# GD32E53x register map
File version: 1.0
CPU: CM33 r0p4, little endian, MPU, FPU, 4 interrupt priority bits
Registers are 32-bit, read-write, reset 0x0 unless marked. A register's access mark holds for its fields unless they carry their own. Offsets are from the block's base; [hi:lo] are bit positions.

## TIMER14 — General level3 timer
Base 0x40014000
Same registers: TIMER42 0x4000E000, TIMER43 0x4000E400, TIMER44 0x4000E800, TIMER41 0x40014400, TIMER40 0x40014C00
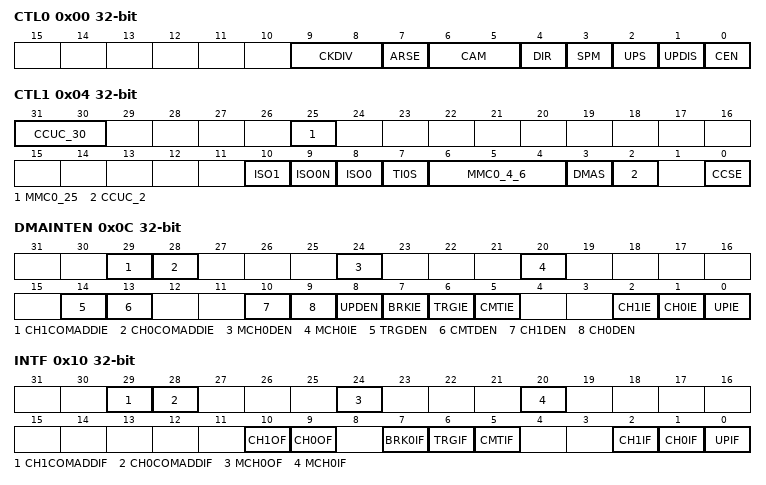
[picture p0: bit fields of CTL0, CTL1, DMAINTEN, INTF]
0x00 CTL0 — Control register 0
  [9:8] CKDIV — Clock division
  [7] ARSE — Auto-reload shadow enable
  [6:5] CAM — Counter align mode selection
  [4] DIR — Direction
  [3] SPM — Single pulse mode
  [2] UPS — Update source
  [1] UPDIS — Update disable
  [0] CEN — Counter enable
0x04 CTL1 — Control register 1
  [31:30] CCUC_30 — Commutation control shadow register update control
  [25] MMC0_25 — Master mode control 0
  [10] ISO1 — Idle state of channel 1 output
  [9] ISO0N — Idle state of multi mode channel 0 complementary output
  [8] ISO0 — Idle state of channel 0 output
  [7] TI0S — Channel 0 trigger input selection
  [6:4] MMC0_4_6 — Master mode control 0
  [3] DMAS — DMA request source selection
  [2] CCUC_2 — Commutation control shadow register update control
  [0] CCSE — Commutation control shadow enable
0x08 SMCFG — Slave mode configuration register
  [7] MSM — Master-slave mode
0x0C DMAINTEN — DMA and interrupt enable register
  [29] CH1COMADDIE — Channel 1 additional compare interrupt enable
  [28] CH0COMADDIE — Channel 0 additional compare interrupt enable
  [24] MCH0DEN — Multi mode channel 0 capture/compare DMA request enable
  [20] MCH0IE — Multi mode channel 0 capture/compare interrupt enable
  [14] TRGDEN — Trigger DMA request enable
  [13] CMTDEN — Commutation DMA request enable
  [10] CH1DEN — Channel 1 capture/compare DMA request enable
  [9] CH0DEN — Channel 0 capture/compare DMA request enable
  [8] UPDEN — Update DMA request enable
  [7] BRKIE — Break interrupt enable
  [6] TRGIE — Trigger interrupt enable
  [5] CMTIE — Commutation interrupt enable
  [2] CH1IE — Channel 1 capture/compare interrupt enable
  [1] CH0IE — Channel 0 capture/compare interrupt enable
  [0] UPIE — Update interrupt enable
0x10 INTF — Interrupt flag register
  [29] CH1COMADDIF — Channel 1 additional compare interrupt flag.
  [28] CH0COMADDIF — Channel 0 additional compare interrupt flag.
  [24] MCH0OF — Multi mode channel 0 over capture flag
  [20] MCH0IF — Multi mode channel 0 capture/compare interrupt flag
  [10] CH1OF — Channel 1 over capture flag
  [9] CH0OF — Channel 0 over capture flag
  [7] BRK0IF — BREAK0 interrupt flag
  [6] TRGIF — Trigger interrupt flag
  [5] CMTIF — Channel commutation interrupt flag
  [2] CH1IF — Channel 1 capture/compare interrupt flag
  [1] CH0IF — Channel 0 capture/compare interrupt flag
  [0] UPIF — Update interrupt flag
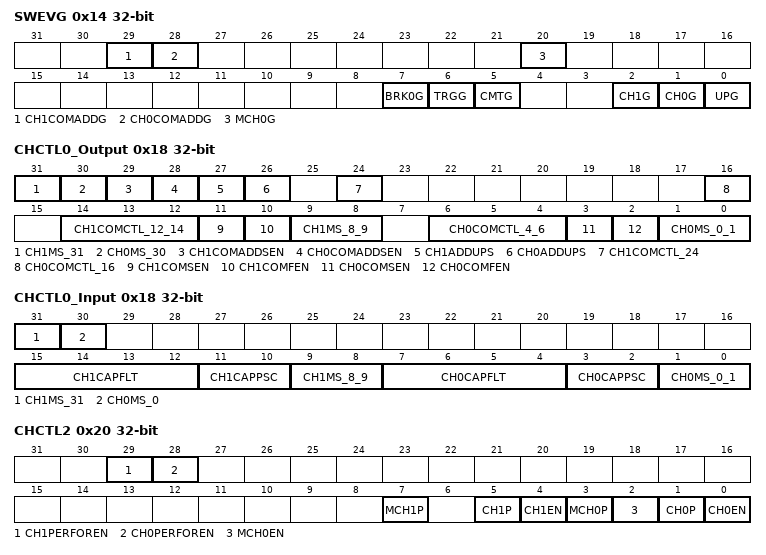
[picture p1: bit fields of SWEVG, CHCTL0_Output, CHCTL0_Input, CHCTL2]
0x14 SWEVG wo — Software event generation register
  [29] CH1COMADDG — Channel 1 additional compare event generation.
  [28] CH0COMADDG — Channel 0 additional compare event generation.
  [20] MCH0G — Multi mode channel 0 capture or compare event generation.
  [7] BRK0G — BREAK0 event generation
  [6] TRGG — Trigger event generation
  [5] CMTG — Channel commutation event generation
  [2] CH1G — Channel 1 capture or compare event generation
  [1] CH0G — Channel 0 capture or compare event generation
  [0] UPG — Update event generation
0x18 CHCTL0_Output — Channel control register 0 (output mode)
  [31] CH1MS_31 — Channel 1 I/O mode selection
  [30] CH0MS_30 — Channel 0 I/O mode selection
  [29] CH1COMADDSEN — Channel 1 additional compare output shadow enable
  [28] CH0COMADDSEN — Channel 0 additional compare output shadow enable
  [27] CH1ADDUPS — Channel 1 additional update source
  [26] CH0ADDUPS — Channel 0 additional update source
  [24] CH1COMCTL_24 — Channel 1 compare output control
  [16] CH0COMCTL_16 — Channel 0 compare output control
  [14:12] CH1COMCTL_12_14 — Channel 1 compare output control
  [11] CH1COMSEN — Channel 1 output compare shadow enable
  [10] CH1COMFEN — Channel 1 output compare fast enable
  [9:8] CH1MS_8_9 — Channel 1 mode selection
  [6:4] CH0COMCTL_4_6 — Channel 0 compare output control
  [3] CH0COMSEN — Channel 0 compare output shadow enable
  [2] CH0COMFEN — Channel 0 output compare fast enable
  [1:0] CH0MS_0_1 — Channel 0 I/O mode selection
0x18 CHCTL0_Input (alternate view of CHCTL0_Output) — Channel control register 0 (input mode)
  [31] CH1MS_31 — Channel 1 I/O mode selection
  [30] CH0MS_0 — Channel 0 I/O mode selection
  [15:12] CH1CAPFLT — Channel 1 input capture filter control
  [11:10] CH1CAPPSC — Channel 1 input capture prescaler
  [9:8] CH1MS_8_9 — Channel 1 mode selection
  [7:4] CH0CAPFLT — Channel 0 input capture filter control
  [3:2] CH0CAPPSC — Channel 0 input capture prescaler
  [1:0] CH0MS_0_1 — Channel 0 mode selection
0x20 CHCTL2 — Channel control register 2
  [29] CH1PERFOREN — Channel 1 in the composite PWM mode, the period point match moment O1CPRE level setting
  [28] CH0PERFOREN — Channel 0 in the composite PWM mode, the period point match moment O0CPRE level setting
  [7] MCH1P — Multi mode channel 1 output polarity
  [5] CH1P — Channel 1 capture/compare polarity
  [4] CH1EN — Channel 1 capture/compare enable
  [3] MCH0P — Multi mode channel 0 output polarity
  [2] MCH0EN — Multi mode channel 0 capture/compare enable
  [1] CH0P — Channel 0 capture/compare polarity
  [0] CH0EN — Channel 0 capture/compare enable
0x24 CNT — Counter register
  [15:0] CNT — This bit-field indicates the current counter value. Writing to this bit-field can change the value of the counter.
0x28 PSC — Prescaler register
  [15:0] PSC — Prescaler value of the counter clock
0x2C CAR reset 0xFFFF — Counter auto reload register
  [15:0] CARL — Counter auto reload value
0x30 CREP0 — Counter repetition register 0
  [7:0] CREP0 — Counter repetition value 0
0x34 CH0CV — Channel 0 capture/compare value register
  [15:0] CH0VAL — Capture/compare value of channel 0
0x38 CH1CV — Channel 1 capture/compare value register
  [15:0] CH1VAL — Capture/compare value of channel 1
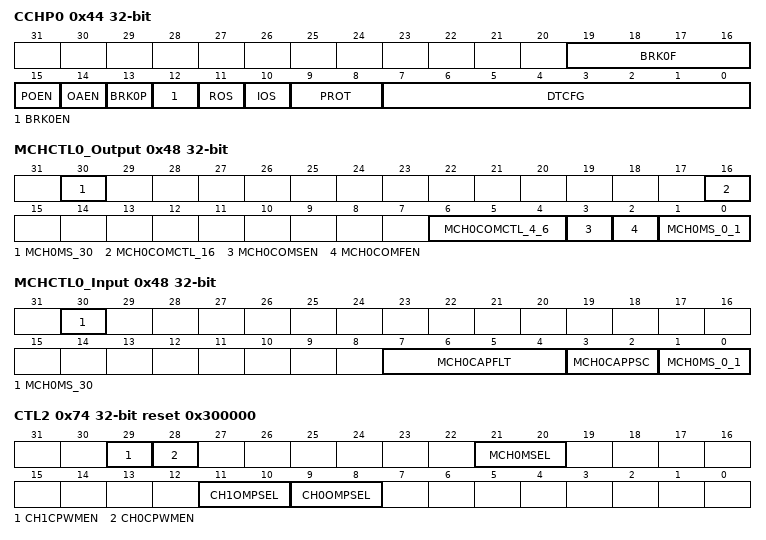
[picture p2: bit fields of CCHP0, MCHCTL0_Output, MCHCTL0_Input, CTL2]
0x44 CCHP0 — Complementary channel protection register 0
  [19:16] BRK0F — BREAK0 input signal filter
  [15] POEN — Primary output enable
  [14] OAEN — Output automatic enable
  [13] BRK0P — BREAK0 input signal polarity
  [12] BRK0EN — BREAK0 input signal enable
  [11] ROS — Run mode off-state enable
  [10] IOS — Idle mode off-state enable
  [9:8] PROT — Complementary register protect control
  [7:0] DTCFG — Dead time configuration
0x48 MCHCTL0_Output — Multi mode channel control register 0
  [30] MCH0MS_30 — Multi mode channel 0 I/O mode selection
  [16] MCH0COMCTL_16 — Multi mode channel 0 compare output control
  [6:4] MCH0COMCTL_4_6 — Multi mode channel 0 output compare control
  [3] MCH0COMSEN — Multi mode channel 0 output compare shadow enable
  [2] MCH0COMFEN — Multi mode channel 0 output compare fast enable
  [1:0] MCH0MS_0_1 — Channel 0 compare output shadow enable
0x48 MCHCTL0_Input (alternate view of MCHCTL0_Output) — Multi mode channel control register 0
  [30] MCH0MS_30 — Multi mode channel 0 I/O mode selection
  [7:4] MCH0CAPFLT — Multi mode channel 0 compare output control
  [3:2] MCH0CAPPSC — Multi mode channel 0 input capture prescaler
  [1:0] MCH0MS_0_1 — Multi mode channel 0 I/O mode selection
0x50 MCHCTL2 — Multi mode channel control register 2
  [1:0] MCH0FP — Multi mode channel 0 capture/compare free polarity
0x54 MCH0CV — Multi mode channel 0 capture/compare value register
  [15:0] MCH0VAL — Capture/compare value of multi mode channel 0.
0x64 CH0COMV_ADD — Channel 0 additional compare value register
  [15:0] CH0COMVAL_ADD — Additional compare value of channel 0
0x68 CH1COMV_ADD — Channel 1 additional compare value register
  [15:0] CH1COMVAL_ADD — Additional compare value of channel 1
0x74 CTL2 reset 0x300000 — Control register 2
  [29] CH1CPWMEN — Channel 1 composite PWM mode enable
  [28] CH0CPWMEN — Channel 0 composite PWM mode enable
  [21:20] MCH0MSEL — Multi mode channel 0 mode select
  [11:10] CH1OMPSEL — Channel 1 output match pulse select
  [9:8] CH0OMPSEL — Channel 0 output match pulse select
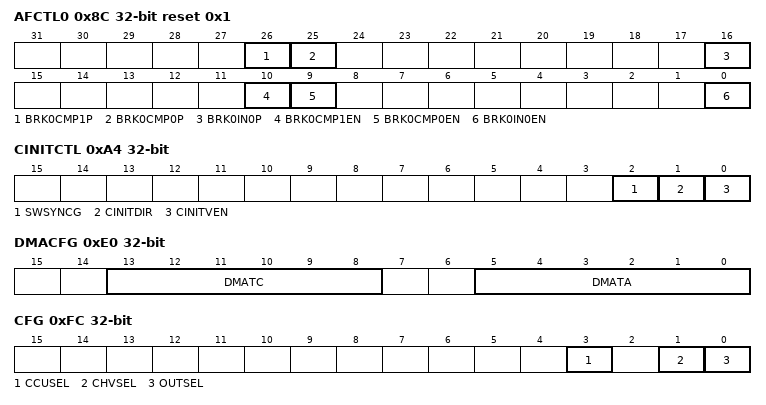
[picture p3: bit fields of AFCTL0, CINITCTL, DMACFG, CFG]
0x8C AFCTL0 reset 0x1 — TIMERx alternate function control register 0
  [26] BRK0CMP1P — BREAK0 CMP1 input polarity
  [25] BRK0CMP0P — BREAK0 CMP0 input polarity
  [16] BRK0IN0P — BREAK0 BRKIN0 alternate function input polarity
  [10] BRK0CMP1EN — BREAK0 CMP1 enable
  [9] BRK0CMP0EN — BREAK0 CMP0 enable
  [0] BRK0IN0EN — BREAK0 BRKIN0 alternate function input enable
0xA4 CINITCTL access per field — Counter initial control register
  [2] SWSYNCG wo — Soft synchronization event generation
  [1] CINITDIR rw — Counter initial count direction
  [0] CINITVEN rw — Counter initial value register enable
0xA8 CINITV — Counter initial value register
  [15:0] CINITVAL — Counter initial value
0xE0 DMACFG — DMA configuration register
  [13:8] DMATC — DMA transfer count
  [5:0] DMATA — DMA transfer access start address
0xE4 DMATB — DMA transfer buffer register
  [31:0] DMATB — DMA transfer buffer
0xFC CFG — Configuration register
  [3] CCUSEL — Commutation control shadow register update select
  [1] CHVSEL — Write CHxVAL register selection bit
  [0] OUTSEL — The output value selection bit
